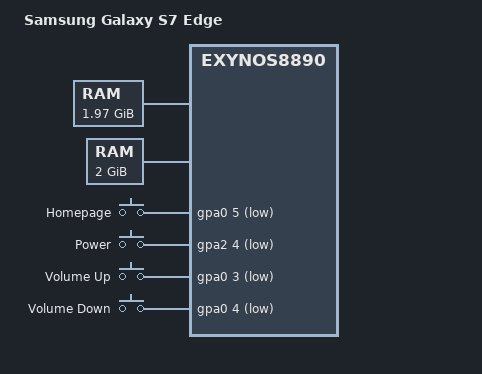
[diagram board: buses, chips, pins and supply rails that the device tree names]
// SPDX-License-Identifier: GPL-2.0
/*
 * Samsung Galaxy S7 Edge (hero2lte/SM-G935F) device tree source
 *
 * Copyright (c) 2021 Samsung Electronics Co., Ltd.
 * Copyright (c) 2022 Gianluca Boiano
 */

/dts-v1/;
#include "exynos8890.dtsi"
#include <dt-bindings/gpio/gpio.h>
#include <dt-bindings/input/input.h>
#include <dt-bindings/interrupt-controller/irq.h>

/ {
	model = "Samsung Galaxy S7 Edge";
	compatible = "samsung,exynos8890-hero2lte", "samsung,exynos8890";
	chassis-type = "handset";

	memory@80000000 {
		device_type = "memory";

		reg = <0x0 0x80000000 0x0 0x7e400000>;
	};

	memory@880000000 {
		device_type = "memory";

		reg = <0x00000008 0x80000000 0x0 0x80000000>;
	};

	gpio-keys {
		compatible = "gpio-keys";
		pinctrl-names = "default";
		pinctrl-0 = <&key_volup &key_voldown &key_power>;

		home-key {
			label = "Homepage";
			linux,code = <KEY_HOMEPAGE>;
			gpios = <&gpa0 5 GPIO_ACTIVE_LOW>;
			wakeup-source;
		};

		power-key {
			label = "Power";
			linux,code = <KEY_POWER>;
			gpios = <&gpa2 4 GPIO_ACTIVE_LOW>;
			wakeup-source;
		};

		volup-key {
			label = "Volume Up";
			linux,code = <KEY_VOLUMEUP>;
			gpios = <&gpa0 3 GPIO_ACTIVE_LOW>;
		};

		voldown-key {
			label = "Volume Down";
			linux,code = <KEY_VOLUMEDOWN>;
			gpios = <&gpa0 4 GPIO_ACTIVE_LOW>;
		};
	};
};

&pinctrl_alive {

	key_home: key-home-pins {
		samsung,pins = "gpa0-5";
		samsung,pin-function = <EXYNOS_PIN_FUNC_F>;
		samsung,pin-pud = <EXYNOS_PIN_PULL_NONE>;
		// samsung,pin-drv = <EXYNOS5420_PIN_DRV_LV1>;
	};

	key_power: key-power-pins {
		samsung,pins = "gpa2-4";
		samsung,pin-function = <EXYNOS_PIN_FUNC_F>;
		samsung,pin-pud = <EXYNOS_PIN_PULL_NONE>;
		// samsung,pin-drv = <EXYNOS5420_PIN_DRV_LV1>;
	};

	key_voldown: key-voldown-pins {
		samsung,pins = "gpa0-4";
		samsung,pin-function = <EXYNOS_PIN_FUNC_F>;
		samsung,pin-pud = <EXYNOS_PIN_PULL_NONE>;
		// samsung,pin-drv = <EXYNOS5420_PIN_DRV_LV1>;
	};

	key_volup: key-volup-pins {
		samsung,pins = "gpa0-3";
		samsung,pin-function = <EXYNOS_PIN_FUNC_F>;
		samsung,pin-pud = <EXYNOS_PIN_PULL_NONE>;
		// samsung,pin-drv = <EXYNOS5420_PIN_DRV_LV1>;
	};
};

&xxti {
	clock-frequency = <26000000>;
};
